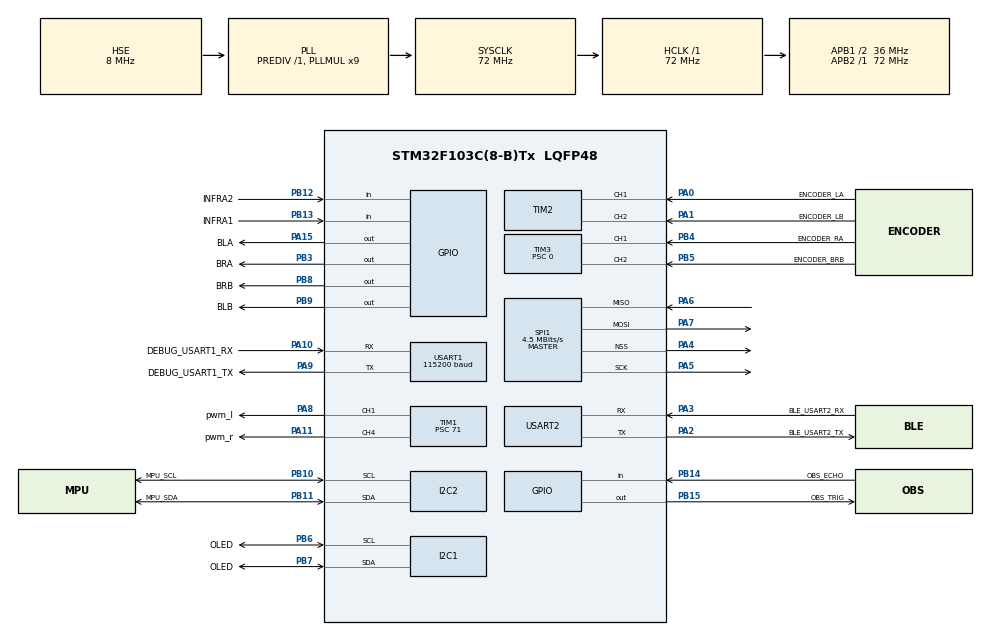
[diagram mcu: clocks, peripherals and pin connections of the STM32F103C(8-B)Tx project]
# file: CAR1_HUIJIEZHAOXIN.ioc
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I2C1.I2C_Mode=I2C_Fast
Mcu.Family=STM32F1
Mcu.Name=STM32F103C(8-B)Tx
Mcu.Package=LQFP48
NVIC.I2C1_EV_IRQn=true\:0\:0\:false\:false\:true\:true\:true\:true
NVIC.PriorityGroup=NVIC_PRIORITYGROUP_4
NVIC.TIM1_UP_IRQn=true\:0\:0\:false\:false\:true\:true\:true\:true
NVIC.TIM2_IRQn=true\:0\:0\:false\:false\:true\:true\:true\:true
NVIC.TIM3_IRQn=true\:0\:0\:false\:false\:true\:true\:true\:true
NVIC.USART1_IRQn=true\:0\:0\:false\:false\:true\:true\:true\:true
NVIC.USART2_IRQn=true\:0\:0\:false\:false\:true\:true\:true\:true
PA0-WKUP.GPIO_Label=ENCODER_LA
PA0-WKUP.Signal=S_TIM2_CH1_ETR
PA1.GPIO_Label=ENCODER_LB
PA1.Signal=S_TIM2_CH2
PA10.GPIO_Label=DEBUG_USART1_RX
PA10.Mode=Asynchronous
PA10.Signal=USART1_RX
PA11.GPIO_Label=pwm_r
PA11.Signal=S_TIM1_CH4
PA13.Mode=Serial_Wire
PA13.Signal=SYS_JTMS-SWDIO
PA14.Mode=Serial_Wire
PA14.Signal=SYS_JTCK-SWCLK
PA15.GPIO_Label=BLA
PA15.Signal=GPIO_Output
PA2.GPIO_Label=BLE_USART2_TX
PA2.Mode=Asynchronous
PA2.Signal=USART2_TX
PA3.GPIO_Label=BLE_USART2_RX
PA3.Mode=Asynchronous
PA3.Signal=USART2_RX
PA4.Mode=NSS_Signal_Hard_Output
PA4.Signal=SPI1_NSS
PA5.Mode=Full_Duplex_Master
PA5.Signal=SPI1_SCK
PA6.Mode=Full_Duplex_Master
PA6.Signal=SPI1_MISO
PA7.Mode=Full_Duplex_Master
PA7.Signal=SPI1_MOSI
PA8.GPIO_Label=pwm_l
PA8.Signal=S_TIM1_CH1
PA9.GPIO_Label=DEBUG_USART1_TX
PA9.Mode=Asynchronous
PA9.Signal=USART1_TX
PB10.GPIO_Label=MPU_SCL
PB10.Mode=I2C
PB10.Signal=I2C2_SCL
PB11.GPIO_Label=MPU_SDA
PB11.Mode=I2C
PB11.Signal=I2C2_SDA
PB12.GPIO_Label=INFRA2
PB12.Signal=GPIO_Input
PB13.GPIO_Label=INFRA1
PB13.Signal=GPIO_Input
PB14.GPIO_Label=OBS_ECHO
PB14.Signal=GPIO_Input
PB15.GPIO_Label=OBS_TRIG
PB15.Signal=GPIO_Output
PB3.GPIO_Label=BRA
PB3.Signal=GPIO_Output
PB4.GPIO_Label=ENCODER_RA
PB4.Signal=S_TIM3_CH1
PB5.GPIO_Label=ENCODER_BRB
PB5.Signal=S_TIM3_CH2
PB6.GPIO_Label=OLED
PB6.Mode=I2C
PB6.Signal=I2C1_SCL
PB7.GPIO_Label=OLED
PB7.Mode=I2C
PB7.Signal=I2C1_SDA
PB8.GPIO_Label=BRB
PB8.Signal=GPIO_Output
PB9.GPIO_Label=BLB
PB9.Signal=GPIO_Output
PD0-OSC_IN.Mode=HSE-External-Oscillator
PD0-OSC_IN.Signal=RCC_OSC_IN
PD1-OSC_OUT.Mode=HSE-External-Oscillator
PD1-OSC_OUT.Signal=RCC_OSC_OUT
ProjectManager.HeapSize=0x200
ProjectManager.StackSize=0x400
ProjectManager.TargetToolchain=STM32CubeIDE
RCC.AHBFreq_Value=72000000
RCC.APB1CLKDivider=RCC_HCLK_DIV2
RCC.APB1Freq_Value=36000000
RCC.APB1TimFreq_Value=72000000
RCC.APB2Freq_Value=72000000
RCC.APB2TimFreq_Value=72000000
RCC.HCLKFreq_Value=72000000
RCC.PLLMUL=RCC_PLL_MUL9
RCC.PLLSourceVirtual=RCC_PLLSOURCE_HSE
RCC.SYSCLKFreq_VALUE=72000000
RCC.SYSCLKSource=RCC_SYSCLKSOURCE_PLLCLK
RCC.USBFreq_Value=72000000
SH.S_TIM1_CH1.0=TIM1_CH1,PWM Generation1 CH1
SH.S_TIM1_CH4.0=TIM1_CH4,PWM Generation4 CH4
SH.S_TIM2_CH1_ETR.0=TIM2_CH1,Encoder_Interface
SH.S_TIM2_CH2.0=TIM2_CH2,Encoder_Interface
SH.S_TIM3_CH1.0=TIM3_CH1,Encoder_Interface
SH.S_TIM3_CH2.0=TIM3_CH2,Encoder_Interface
SPI1.BaudRatePrescaler=SPI_BAUDRATEPRESCALER_16
SPI1.CalculateBaudRate=4.5 MBits/s
SPI1.Direction=SPI_DIRECTION_2LINES
SPI1.Mode=SPI_MODE_MASTER
SPI1.VirtualNSS=VM_NSSHARD
SPI1.VirtualType=VM_MASTER
TIM1.AutoReloadPreload=TIM_AUTORELOAD_PRELOAD_ENABLE
TIM1.Channel-PWM\ Generation1\ CH1=TIM_CHANNEL_1
TIM1.Channel-PWM\ Generation4\ CH4=TIM_CHANNEL_4
TIM1.Period=65535
TIM1.Prescaler=71
TIM1.Pulse-PWM\ Generation1\ CH1=0
TIM1.Pulse-PWM\ Generation4\ CH4=0
TIM2.AutoReloadPreload=TIM_AUTORELOAD_PRELOAD_DISABLE
TIM2.EncoderMode=TIM_ENCODERMODE_TI12
TIM3.AutoReloadPreload=TIM_AUTORELOAD_PRELOAD_DISABLE
TIM3.EncoderMode=TIM_ENCODERMODE_TI12
TIM3.Period=65535
TIM3.Prescaler=0
TIM4.AutoReloadPreload=TIM_AUTORELOAD_PRELOAD_ENABLE
TIM4.Period=59999
TIM4.Prescaler=71
USART1.BaudRate=115200
USART1.VirtualMode=VM_ASYNC
USART2.VirtualMode=VM_ASYNC
VP_TIM4_VS_ClockSourceINT.Mode=Internal
board=custom

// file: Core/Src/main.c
/* USER CODE BEGIN Header */
/**
  ******************************************************************************
  * @file           : main.c
  * @brief          : Main program body
  ******************************************************************************
  * @attention
  *
  * Copyright (c) 2022 STMicroelectronics.
  * All rights reserved.
  *
  * This software is licensed under terms that can be found in the LICENSE file
  * in the root directory of this software component.
  * If no LICENSE file comes with this software, it is provided AS-IS.
  *
  ******************************************************************************
  */
/* USER CODE END Header */
#include "main.h"
#include "i2c.h"
#include "spi.h"
#include "tim.h"
#include "usart.h"
#include "gpio.h"

/* USER CODE BEGIN Includes */
#include"run_main.h"
/* USER CODE END Includes */

void SystemClock_Config(void);

int main(void)
{

  /* MCU Configuration--------------------------------------------------------*/

  /* Reset of all peripherals, Initializes the Flash interface and the Systick. */
  HAL_Init();

  /* Configure the system clock */
  SystemClock_Config();

  /* Initialize all configured peripherals */
  MX_GPIO_Init();
  MX_TIM2_Init();
  MX_I2C1_Init();
  MX_USART1_UART_Init();
  MX_TIM3_Init();
  MX_USART2_UART_Init();
  MX_I2C2_Init();
  MX_SPI1_Init();
  MX_TIM4_Init();
  MX_TIM1_Init();
  /* USER CODE BEGIN 2 */
  HAL_TIM_OC_Start_IT(&htim3, TIM_CHANNEL_1); //�????�定时超声波??�障
  /* USER CODE END 2 */

  /* Infinite loop */
  /* USER CODE BEGIN WHILE */
  while (1)
  {
    run_main();
    /* USER CODE END WHILE */

  }
}

void SystemClock_Config(void)
{
  RCC_OscInitTypeDef RCC_OscInitStruct = {0};
  RCC_ClkInitTypeDef RCC_ClkInitStruct = {0};

  /** Initializes the RCC Oscillators according to the specified parameters
  * in the RCC_OscInitTypeDef structure.
  */
  RCC_OscInitStruct.OscillatorType = RCC_OSCILLATORTYPE_HSE;
  RCC_OscInitStruct.HSEState = RCC_HSE_ON;
  RCC_OscInitStruct.HSEPredivValue = RCC_HSE_PREDIV_DIV1;
  RCC_OscInitStruct.HSIState = RCC_HSI_ON;
  RCC_OscInitStruct.PLL.PLLState = RCC_PLL_ON;
  RCC_OscInitStruct.PLL.PLLSource = RCC_PLLSOURCE_HSE;
  RCC_OscInitStruct.PLL.PLLMUL = RCC_PLL_MUL9;
  if (HAL_RCC_OscConfig(&RCC_OscInitStruct) != HAL_OK)
  {
    Error_Handler();
  }

  /** Initializes the CPU, AHB and APB buses clocks
  */
  RCC_ClkInitStruct.ClockType = RCC_CLOCKTYPE_HCLK|RCC_CLOCKTYPE_SYSCLK
                              |RCC_CLOCKTYPE_PCLK1|RCC_CLOCKTYPE_PCLK2;
  RCC_ClkInitStruct.SYSCLKSource = RCC_SYSCLKSOURCE_PLLCLK;
  RCC_ClkInitStruct.AHBCLKDivider = RCC_SYSCLK_DIV1;
  RCC_ClkInitStruct.APB1CLKDivider = RCC_HCLK_DIV2;
  RCC_ClkInitStruct.APB2CLKDivider = RCC_HCLK_DIV1;

  if (HAL_RCC_ClockConfig(&RCC_ClkInitStruct, FLASH_LATENCY_2) != HAL_OK)
  {
    Error_Handler();
  }
}

void Error_Handler(void)
{
  __disable_irq();
  while (1)
  {
  }
}
